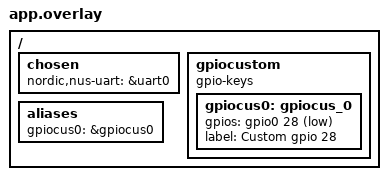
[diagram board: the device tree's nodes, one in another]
/*
 * Copyright (c) 2022 Nordic Semiconductor ASA
 *
 * SPDX-License-Identifier: LicenseRef-Nordic-5-Clause
 */

/ {
	chosen {
		nordic,nus-uart = &uart0;
	};
};

/ {
    gpiocustom {
        compatible = "gpio-keys";
        gpiocus0: gpiocus_0 {
            gpios = <&gpio0 28 GPIO_ACTIVE_LOW>;
            label = "Custom gpio 28";
        };
    };
    aliases {
        gpiocus0 = &gpiocus0;
    };
};
